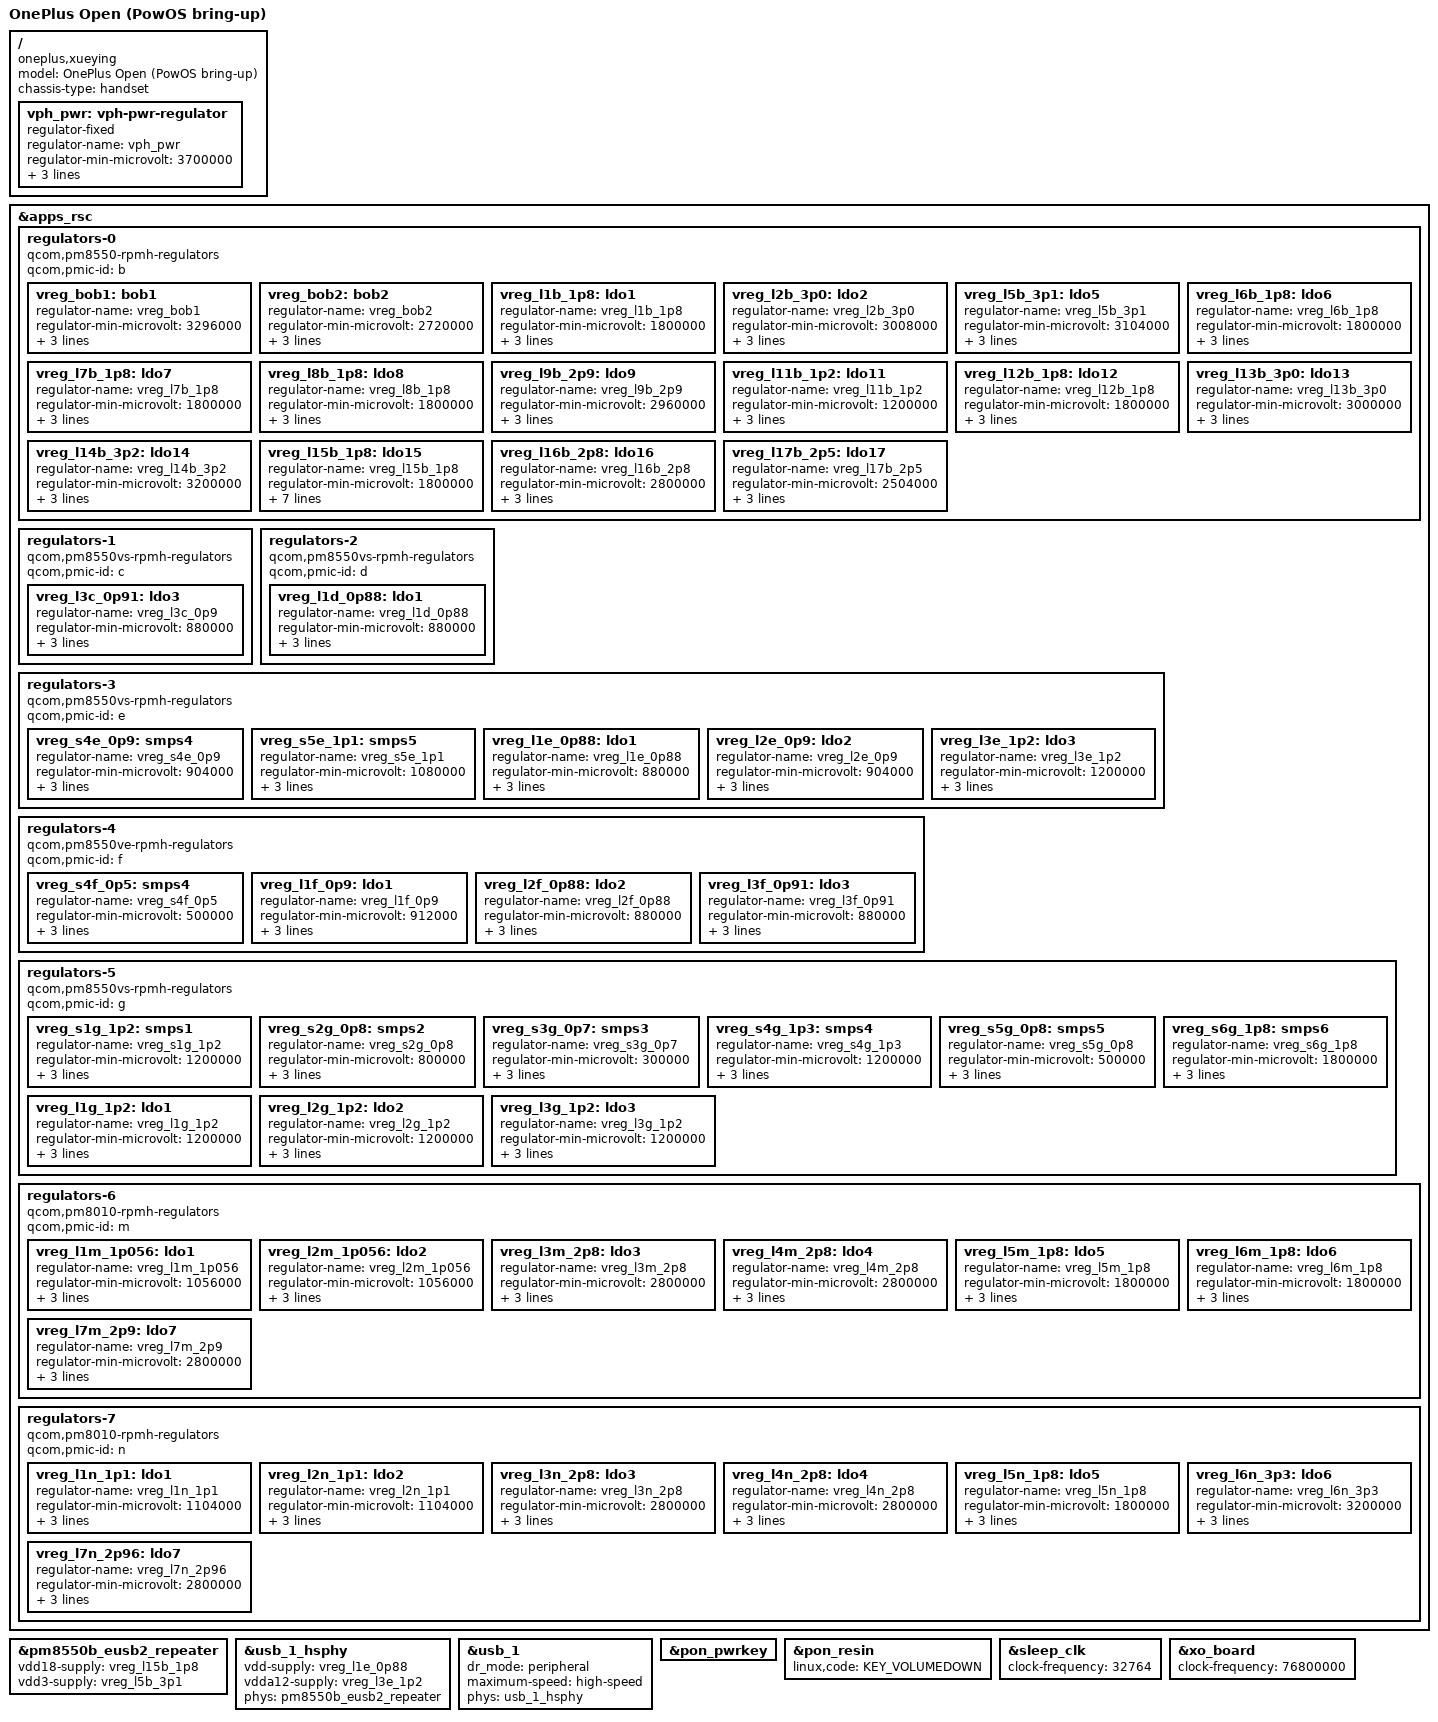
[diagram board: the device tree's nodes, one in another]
// SPDX-License-Identifier: BSD-3-Clause
/*
 * OnePlus Open (xueying, CPH2551; = Oppo Find N3 PHN110) - PowOS BRING-UP device tree.
 *
 * Goal of this version: boot via `fastboot boot` (RAM only) to a USB network shell. Nothing else is enabled:
 * no display/touch/audio/hinge, NO UFS (the phone's storage is not touched at all), no remoteprocs.
 *
 * Based on mainline sm8550-samsung-q5q.dts (Galaxy Z Fold5: same SoC, also a foldable; BSD-3-Clause,
 * (c) 2024 Alexandru Marc Serdeliuc, David Wronek, 2022 Linaro) and sm8550-qrd.dts for the USB path.
 */

/dts-v1/;

#include <dt-bindings/input/linux-event-codes.h>
#include <dt-bindings/regulator/qcom,rpmh-regulator.h>
#include "sm8550.dtsi"
#include "pm8550.dtsi"
#include "pm8550b.dtsi"
#include "pm8550vs.dtsi"
#include "pmk8550.dtsi"
/*
 * Per-unit facts read from the phone's own (stock) device tree on day 1 by `phone.sh dump`:
 * qcom,msm-id / qcom,board-id (the bootloader picks a DTB by them) and the splash framebuffer the bootloader
 * leaves lit. Until then the file holds placeholders and make-bootimg.sh refuses to build.
 */
#include "sm8550-oneplus-xueying-board.dtsi"

/ {
	model = "OnePlus Open (PowOS bring-up)";
	compatible = "oneplus,xueying", "qcom,sm8550";
	chassis-type = "handset";

	vph_pwr: vph-pwr-regulator {
		compatible = "regulator-fixed";
		regulator-name = "vph_pwr";
		regulator-min-microvolt = <3700000>;
		regulator-max-microvolt = <3700000>;
		regulator-always-on;
		regulator-boot-on;
	};
};

/*
 * HACK: the Fold5's RPMh regulator table, verbatim. SM8550 phones share Qualcomm's reference power grid, so the
 * rails the USB path uses (l1e/l3e for the eUSB2 PHY, l5b/l15b for its repeater) carry the same names and
 * voltages - but the Open's own table must be read from its downstream DT (OnePlusOSS
 * oneplus/sm8550_b_16.0.0_oneplus_open) and replace this before anything beyond USB is enabled.
 */
&apps_rsc {
	regulators-0 {
		compatible = "qcom,pm8550-rpmh-regulators";
		qcom,pmic-id = "b";

		vreg_bob1: bob1 {
			regulator-name = "vreg_bob1";
			regulator-min-microvolt = <3296000>;
			regulator-max-microvolt = <3960000>;
			regulator-initial-mode = <RPMH_REGULATOR_MODE_HPM>;
		};

		vreg_bob2: bob2 {
			regulator-name = "vreg_bob2";
			regulator-min-microvolt = <2720000>;
			regulator-max-microvolt = <3960000>;
			regulator-initial-mode = <RPMH_REGULATOR_MODE_HPM>;
		};

		vreg_l1b_1p8: ldo1 {
			regulator-name = "vreg_l1b_1p8";
			regulator-min-microvolt = <1800000>;
			regulator-max-microvolt = <1800000>;
			regulator-initial-mode = <RPMH_REGULATOR_MODE_HPM>;
		};

		vreg_l2b_3p0: ldo2 {
			regulator-name = "vreg_l2b_3p0";
			regulator-min-microvolt = <3008000>;
			regulator-max-microvolt = <3008000>;
			regulator-initial-mode = <RPMH_REGULATOR_MODE_HPM>;
		};

		vreg_l5b_3p1: ldo5 {
			regulator-name = "vreg_l5b_3p1";
			regulator-min-microvolt = <3104000>;
			regulator-max-microvolt = <3104000>;
			regulator-initial-mode = <RPMH_REGULATOR_MODE_HPM>;
		};

		vreg_l6b_1p8: ldo6 {
			regulator-name = "vreg_l6b_1p8";
			regulator-min-microvolt = <1800000>;
			regulator-max-microvolt = <3008000>;
			regulator-initial-mode = <RPMH_REGULATOR_MODE_HPM>;
		};

		vreg_l7b_1p8: ldo7 {
			regulator-name = "vreg_l7b_1p8";
			regulator-min-microvolt = <1800000>;
			regulator-max-microvolt = <3008000>;
			regulator-initial-mode = <RPMH_REGULATOR_MODE_HPM>;
		};

		vreg_l8b_1p8: ldo8 {
			regulator-name = "vreg_l8b_1p8";
			regulator-min-microvolt = <1800000>;
			regulator-max-microvolt = <3008000>;
			regulator-initial-mode = <RPMH_REGULATOR_MODE_HPM>;
		};

		vreg_l9b_2p9: ldo9 {
			regulator-name = "vreg_l9b_2p9";
			regulator-min-microvolt = <2960000>;
			regulator-max-microvolt = <3008000>;
			regulator-initial-mode = <RPMH_REGULATOR_MODE_HPM>;
		};

		vreg_l11b_1p2: ldo11 {
			regulator-name = "vreg_l11b_1p2";
			regulator-min-microvolt = <1200000>;
			regulator-max-microvolt = <1504000>;
			regulator-initial-mode = <RPMH_REGULATOR_MODE_HPM>;
		};

		vreg_l12b_1p8: ldo12 {
			regulator-name = "vreg_l12b_1p8";
			regulator-min-microvolt = <1800000>;
			regulator-max-microvolt = <1800000>;
			regulator-initial-mode = <RPMH_REGULATOR_MODE_HPM>;
		};

		vreg_l13b_3p0: ldo13 {
			regulator-name = "vreg_l13b_3p0";
			regulator-min-microvolt = <3000000>;
			regulator-max-microvolt = <3000000>;
			regulator-initial-mode = <RPMH_REGULATOR_MODE_HPM>;
		};

		vreg_l14b_3p2: ldo14 {
			regulator-name = "vreg_l14b_3p2";
			regulator-min-microvolt = <3200000>;
			regulator-max-microvolt = <3200000>;
			regulator-initial-mode = <RPMH_REGULATOR_MODE_HPM>;
		};

		vreg_l15b_1p8: ldo15 {
			regulator-name = "vreg_l15b_1p8";
			regulator-min-microvolt = <1800000>;
			regulator-max-microvolt = <1800000>;
			regulator-initial-mode = <RPMH_REGULATOR_MODE_HPM>;
			regulator-allow-set-load;
			regulator-allowed-modes = <RPMH_REGULATOR_MODE_LPM
						   RPMH_REGULATOR_MODE_HPM>;
			regulator-always-on;
		};

		vreg_l16b_2p8: ldo16 {
			regulator-name = "vreg_l16b_2p8";
			regulator-min-microvolt = <2800000>;
			regulator-max-microvolt = <2800000>;
			regulator-initial-mode = <RPMH_REGULATOR_MODE_HPM>;
		};

		vreg_l17b_2p5: ldo17 {
			regulator-name = "vreg_l17b_2p5";
			regulator-min-microvolt = <2504000>;
			regulator-max-microvolt = <2504000>;
			regulator-initial-mode = <RPMH_REGULATOR_MODE_HPM>;
		};
	};

	regulators-1 {
		compatible = "qcom,pm8550vs-rpmh-regulators";
		qcom,pmic-id = "c";

		vreg_l3c_0p91: ldo3 {
			regulator-name = "vreg_l3c_0p9";
			regulator-min-microvolt = <880000>;
			regulator-max-microvolt = <912000>;
			regulator-initial-mode = <RPMH_REGULATOR_MODE_HPM>;
		};
	};

	regulators-2 {
		compatible = "qcom,pm8550vs-rpmh-regulators";
		qcom,pmic-id = "d";

		vreg_l1d_0p88: ldo1 {
			regulator-name = "vreg_l1d_0p88";
			regulator-min-microvolt = <880000>;
			regulator-max-microvolt = <920000>;
			regulator-initial-mode = <RPMH_REGULATOR_MODE_HPM>;
		};
	};

	regulators-3 {
		compatible = "qcom,pm8550vs-rpmh-regulators";
		qcom,pmic-id = "e";

		vreg_s4e_0p9: smps4 {
			regulator-name = "vreg_s4e_0p9";
			regulator-min-microvolt = <904000>;
			regulator-max-microvolt = <984000>;
			regulator-initial-mode = <RPMH_REGULATOR_MODE_HPM>;
		};

		vreg_s5e_1p1: smps5 {
			regulator-name = "vreg_s5e_1p1";
			regulator-min-microvolt = <1080000>;
			regulator-max-microvolt = <1120000>;
			regulator-initial-mode = <RPMH_REGULATOR_MODE_HPM>;
		};

		vreg_l1e_0p88: ldo1 {
			regulator-name = "vreg_l1e_0p88";
			regulator-min-microvolt = <880000>;
			regulator-max-microvolt = <880000>;
			regulator-initial-mode = <RPMH_REGULATOR_MODE_HPM>;
		};

		vreg_l2e_0p9: ldo2 {
			regulator-name = "vreg_l2e_0p9";
			regulator-min-microvolt = <904000>;
			regulator-max-microvolt = <970000>;
			regulator-initial-mode = <RPMH_REGULATOR_MODE_HPM>;
		};

		vreg_l3e_1p2: ldo3 {
			regulator-name = "vreg_l3e_1p2";
			regulator-min-microvolt = <1200000>;
			regulator-max-microvolt = <1200000>;
			regulator-initial-mode = <RPMH_REGULATOR_MODE_HPM>;
		};
	};

	regulators-4 {
		compatible = "qcom,pm8550ve-rpmh-regulators";
		qcom,pmic-id = "f";

		vreg_s4f_0p5: smps4 {
			regulator-name = "vreg_s4f_0p5";
			regulator-min-microvolt = <500000>;
			regulator-max-microvolt = <700000>;
			regulator-initial-mode = <RPMH_REGULATOR_MODE_HPM>;
		};

		vreg_l1f_0p9: ldo1 {
			regulator-name = "vreg_l1f_0p9";
			regulator-min-microvolt = <912000>;
			regulator-max-microvolt = <912000>;
			regulator-initial-mode = <RPMH_REGULATOR_MODE_HPM>;
		};

		vreg_l2f_0p88: ldo2 {
			regulator-name = "vreg_l2f_0p88";
			regulator-min-microvolt = <880000>;
			regulator-max-microvolt = <912000>;
			regulator-initial-mode = <RPMH_REGULATOR_MODE_HPM>;
		};

		vreg_l3f_0p91: ldo3 {
			regulator-name = "vreg_l3f_0p91";
			regulator-min-microvolt = <880000>;
			regulator-max-microvolt = <912000>;
			regulator-initial-mode = <RPMH_REGULATOR_MODE_HPM>;
		};
	};

	regulators-5 {
		compatible = "qcom,pm8550vs-rpmh-regulators";
		qcom,pmic-id = "g";

		vreg_s1g_1p2: smps1 {
			regulator-name = "vreg_s1g_1p2";
			regulator-min-microvolt = <1200000>;
			regulator-max-microvolt = <1300000>;
			regulator-initial-mode = <RPMH_REGULATOR_MODE_HPM>;
		};

		vreg_s2g_0p8: smps2 {
			regulator-name = "vreg_s2g_0p8";
			regulator-min-microvolt = <800000>;
			regulator-max-microvolt = <1000000>;
			regulator-initial-mode = <RPMH_REGULATOR_MODE_HPM>;
		};

		vreg_s3g_0p7: smps3 {
			regulator-name = "vreg_s3g_0p7";
			regulator-min-microvolt = <300000>;
			regulator-max-microvolt = <1004000>;
			regulator-initial-mode = <RPMH_REGULATOR_MODE_HPM>;
		};

		vreg_s4g_1p3: smps4 {
			regulator-name = "vreg_s4g_1p3";
			regulator-min-microvolt = <1200000>;
			regulator-max-microvolt = <1352000>;
			regulator-initial-mode = <RPMH_REGULATOR_MODE_HPM>;
		};

		vreg_s5g_0p8: smps5 {
			regulator-name = "vreg_s5g_0p8";
			regulator-min-microvolt = <500000>;
			regulator-max-microvolt = <1004000>;
			regulator-initial-mode = <RPMH_REGULATOR_MODE_HPM>;
		};

		vreg_s6g_1p8: smps6 {
			regulator-name = "vreg_s6g_1p8";
			regulator-min-microvolt = <1800000>;
			regulator-max-microvolt = <2000000>;
			regulator-initial-mode = <RPMH_REGULATOR_MODE_HPM>;
		};

		vreg_l1g_1p2: ldo1 {
			regulator-name = "vreg_l1g_1p2";
			regulator-min-microvolt = <1200000>;
			regulator-max-microvolt = <1200000>;
			regulator-initial-mode = <RPMH_REGULATOR_MODE_HPM>;
		};

		vreg_l2g_1p2: ldo2 {
			regulator-name = "vreg_l2g_1p2";
			regulator-min-microvolt = <1200000>;
			regulator-max-microvolt = <1200000>;
			regulator-initial-mode = <RPMH_REGULATOR_MODE_HPM>;
		};

		vreg_l3g_1p2: ldo3 {
			regulator-name = "vreg_l3g_1p2";
			regulator-min-microvolt = <1200000>;
			regulator-max-microvolt = <1200000>;
			regulator-initial-mode = <RPMH_REGULATOR_MODE_HPM>;
		};
	};

	regulators-6 {
		compatible = "qcom,pm8010-rpmh-regulators";
		qcom,pmic-id = "m";

		vreg_l1m_1p056: ldo1 {
			regulator-name = "vreg_l1m_1p056";
			regulator-min-microvolt = <1056000>;
			regulator-max-microvolt = <1056000>;
			regulator-initial-mode = <RPMH_REGULATOR_MODE_HPM>;
		};

		vreg_l2m_1p056: ldo2 {
			regulator-name = "vreg_l2m_1p056";
			regulator-min-microvolt = <1056000>;
			regulator-max-microvolt = <1056000>;
			regulator-initial-mode = <RPMH_REGULATOR_MODE_HPM>;
		};

		vreg_l3m_2p8: ldo3 {
			regulator-name = "vreg_l3m_2p8";
			regulator-min-microvolt = <2800000>;
			regulator-max-microvolt = <2800000>;
			regulator-initial-mode = <RPMH_REGULATOR_MODE_HPM>;
		};

		vreg_l4m_2p8: ldo4 {
			regulator-name = "vreg_l4m_2p8";
			regulator-min-microvolt = <2800000>;
			regulator-max-microvolt = <2800000>;
			regulator-initial-mode = <RPMH_REGULATOR_MODE_HPM>;
		};

		vreg_l5m_1p8: ldo5 {
			regulator-name = "vreg_l5m_1p8";
			regulator-min-microvolt = <1800000>;
			regulator-max-microvolt = <1800000>;
			regulator-initial-mode = <RPMH_REGULATOR_MODE_HPM>;
		};

		vreg_l6m_1p8: ldo6 {
			regulator-name = "vreg_l6m_1p8";
			regulator-min-microvolt = <1800000>;
			regulator-max-microvolt = <1800000>;
			regulator-initial-mode = <RPMH_REGULATOR_MODE_HPM>;
		};

		vreg_l7m_2p9: ldo7 {
			regulator-name = "vreg_l7m_2p9";
			regulator-min-microvolt = <2800000>;
			regulator-max-microvolt = <2904000>;
			regulator-initial-mode = <RPMH_REGULATOR_MODE_HPM>;
		};
	};

	regulators-7 {
		compatible = "qcom,pm8010-rpmh-regulators";
		qcom,pmic-id = "n";

		vreg_l1n_1p1: ldo1 {
			regulator-name = "vreg_l1n_1p1";
			regulator-min-microvolt = <1104000>;
			regulator-max-microvolt = <1200000>;
			regulator-initial-mode = <RPMH_REGULATOR_MODE_HPM>;
		};

		vreg_l2n_1p1: ldo2 {
			regulator-name = "vreg_l2n_1p1";
			regulator-min-microvolt = <1104000>;
			regulator-max-microvolt = <1200000>;
			regulator-initial-mode = <RPMH_REGULATOR_MODE_HPM>;
		};

		vreg_l3n_2p8: ldo3 {
			regulator-name = "vreg_l3n_2p8";
			regulator-min-microvolt = <2800000>;
			regulator-max-microvolt = <3000000>;
			regulator-initial-mode = <RPMH_REGULATOR_MODE_HPM>;
		};

		vreg_l4n_2p8: ldo4 {
			regulator-name = "vreg_l4n_2p8";
			regulator-min-microvolt = <2800000>;
			regulator-max-microvolt = <3300000>;
			regulator-initial-mode = <RPMH_REGULATOR_MODE_HPM>;
		};

		vreg_l5n_1p8: ldo5 {
			regulator-name = "vreg_l5n_1p8";
			regulator-min-microvolt = <1800000>;
			regulator-max-microvolt = <1800000>;
			regulator-initial-mode = <RPMH_REGULATOR_MODE_HPM>;
		};

		vreg_l6n_3p3: ldo6 {
			regulator-name = "vreg_l6n_3p3";
			regulator-min-microvolt = <3200000>;
			regulator-max-microvolt = <3200000>;
			regulator-initial-mode = <RPMH_REGULATOR_MODE_HPM>;
		};

		vreg_l7n_2p96: ldo7 {
			regulator-name = "vreg_l7n_2p96";
			regulator-min-microvolt = <2800000>;
			regulator-max-microvolt = <2960000>;
			regulator-initial-mode = <RPMH_REGULATOR_MODE_HPM>;
		};
	};
};

/* USB: device (gadget) mode only, USB 2 only - no Type-C/role-switch graph, no USB 3/DP PHY. Enough for the
 * bring-up shell; host mode and SuperSpeed come with the pmic_glink work later. */
&pm8550b_eusb2_repeater {
	vdd18-supply = <&vreg_l15b_1p8>;
	vdd3-supply = <&vreg_l5b_3p1>;
};

&usb_1_hsphy {
	vdd-supply = <&vreg_l1e_0p88>;
	vdda12-supply = <&vreg_l3e_1p2>;
	phys = <&pm8550b_eusb2_repeater>;
	status = "okay";
};

&usb_1 {
	dr_mode = "peripheral";
	maximum-speed = "high-speed";
	phys = <&usb_1_hsphy>;
	phy-names = "usb2-phy";
	/delete-property/ usb-role-switch;
	status = "okay";
};

&pon_pwrkey {
	status = "okay";
};

&pon_resin {
	linux,code = <KEY_VOLUMEDOWN>;
	status = "okay";
};

&sleep_clk {
	clock-frequency = <32764>;
};

&xo_board {
	clock-frequency = <76800000>;
};
